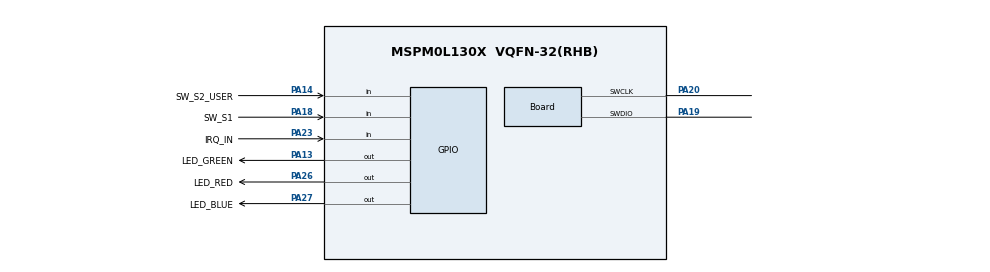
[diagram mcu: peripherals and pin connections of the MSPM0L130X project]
// @cliArgs --device "MSPM0L130X" --package "VQFN-32(RHB)" --part "Default"
// @cliArgs --board /ti/boards/LP_MSPM0L1306 --rtos nortos

/**
 * Import the modules used in this configuration.
 */
const Board  = scripting.addModule("/ti/driverlib/Board");
const GPIO   = scripting.addModule("/ti/driverlib/GPIO", {}, false);
const GPIO1  = GPIO.addInstance();
const I2C    = scripting.addModule("/ti/driverlib/I2C", {}, false);
const I2C1   = I2C.addInstance();
const SYSCTL = scripting.addModule("/ti/driverlib/SYSCTL");
const TIMER  = scripting.addModule("/ti/driverlib/TIMER", {}, false);
const TIMER1 = TIMER.addInstance();
const TIMER2 = TIMER.addInstance();

/**
 * Write custom configuration values to the imported modules.
 */
Board.configureUnused             = true;
Board.genPeriphPinFile            = true;
Board.peripheral.$assign          = "DEBUGSS";
Board.peripheral.swclkPin.$assign = "PA20";
Board.peripheral.swdioPin.$assign = "PA19";
Board.genFileMod.$name            = "ti_driverlib_BoardPins0";

GPIO1.$name                              = "GPIO_A";
GPIO1.associatedPins.create(6);
GPIO1.associatedPins[0].$name            = "LED_GREEN";
GPIO1.associatedPins[0].assignedPin      = "13";
GPIO1.associatedPins[0].assignedPort     = "PORTA";
GPIO1.associatedPins[0].pin.$assign      = "PA13";
GPIO1.associatedPins[1].$name            = "LED_RED";
GPIO1.associatedPins[1].assignedPin      = "26";
GPIO1.associatedPins[1].assignedPort     = "PORTA";
GPIO1.associatedPins[1].pin.$assign      = "PA26";
GPIO1.associatedPins[2].$name            = "LED_BLUE";
GPIO1.associatedPins[2].assignedPin      = "27";
GPIO1.associatedPins[2].assignedPort     = "PORTA";
GPIO1.associatedPins[2].pin.$assign      = "PA27";
GPIO1.associatedPins[3].direction        = "INPUT";
GPIO1.associatedPins[3].internalResistor = "PULL_UP";
GPIO1.associatedPins[3].inputFilter      = "8_CYCLES";
GPIO1.associatedPins[3].interruptEn      = true;
GPIO1.associatedPins[3].assignedPort     = "PORTA";
GPIO1.associatedPins[3].assignedPin      = "14";
GPIO1.associatedPins[3].polarity         = "RISE_FALL";
GPIO1.associatedPins[3].$name            = "SW_S2_USER";
GPIO1.associatedPins[3].pin.$assign      = "PA14";
GPIO1.associatedPins[4].initialValue     = "SET";
GPIO1.associatedPins[4].subOutputPolicy  = "TOGGLE";
GPIO1.associatedPins[4].subChanID        = 1;
GPIO1.associatedPins[4].direction        = "INPUT";
GPIO1.associatedPins[4].assignedPin      = "23";
GPIO1.associatedPins[4].$name            = "IRQ_IN";
GPIO1.associatedPins[4].internalResistor = "PULL_UP";
GPIO1.associatedPins[4].assignedPort     = "PORTA";
GPIO1.associatedPins[4].inputFilter      = "3_CYCLES";
GPIO1.associatedPins[4].interruptEn      = true;
GPIO1.associatedPins[4].polarity         = "FALL";
GPIO1.associatedPins[4].pin.$assign      = "PA23";
GPIO1.associatedPins[5].direction        = "INPUT";
GPIO1.associatedPins[5].assignedPort     = "PORTA";
GPIO1.associatedPins[5].assignedPin      = "18";
GPIO1.associatedPins[5].interruptEn      = true;
GPIO1.associatedPins[5].polarity         = "RISE_FALL";
GPIO1.associatedPins[5].$name            = "SW_S1";
GPIO1.associatedPins[5].pin.$assign      = "PA18";

I2C1.basicTargetAddress                = 0x48;
I2C1.advTargetClkStretch               = false;
I2C1.basicEnableController             = true;
I2C1.$name                             = "I2C_CONTROLLER";
I2C1.intController                     = ["NACK","RXFIFO_TRIGGER","RX_DONE","START","TXFIFO_TRIGGER","TX_DONE"];
I2C1.advControllerClkStretch           = false;
I2C1.advControllerTXFIFOTRIG           = "BYTES_1";

SYSCTL.clockTreeEn = true;
SYSCTL.powerPolicy = "STANDBY1";

TIMER1.interrupts                  = ["ZERO"];
TIMER1.timerPeriod                 = "10 ms";
TIMER1.timerClkSrc                 = "LFCLK";
TIMER1.event1ControllerInterruptEn = ["ZERO_EVENT"];
TIMER1.$name                       = "TIMG_DELAY_BLOCKING";

TIMER2.timerClkPrescale            = 256;
TIMER2.interrupts                  = ["ZERO"];
TIMER2.timerPeriod                 = "10 ms";
TIMER2.timerClkSrc                 = "LFCLK";
TIMER2.event1ControllerInterruptEn = ["ZERO_EVENT"];
TIMER2.$name                       = "TIMG_DELAY_NO_BLOCKING";
